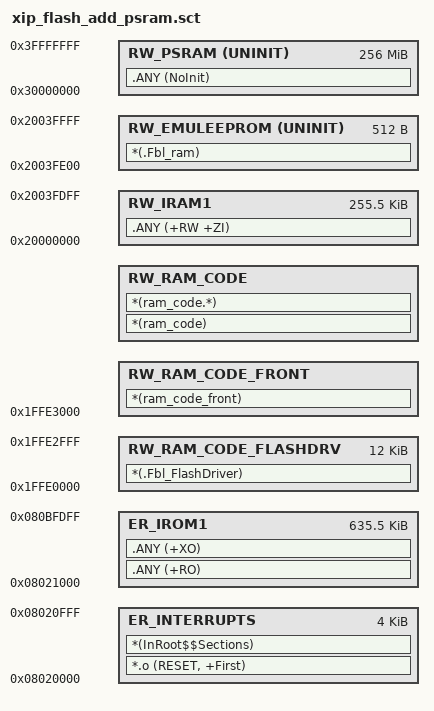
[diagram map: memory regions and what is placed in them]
; *************************************************************
; *** Scatter-Loading Description File generated by uVision ***
; *************************************************************
LR_INTERRUPTS 0x08020000 0x00001000  {    ; load region size_region
  ER_INTERRUPTS 0x08020000 0x00001000  {  ; load address = execution address
   *.o (RESET, +First)
   *(InRoot$$Sections)
  }
}

LR_IROM1 0x08021000 0x0009EE00  {    ; load region size_region
  ER_IROM1 0x08021000 0x0009EE00  {  ; load address = execution address
   .ANY (+RO)
   .ANY (+XO)
  }
  RW_RAM_CODE_FLASHDRV 0x1FFE0000 0x00003000 {
    *(.Fbl_FlashDriver)
  }
  RW_RAM_CODE_FRONT 0x1FFE3000  {
    *(ram_code_front)
  }
  RW_RAM_CODE +0 {
   *(ram_code)
   *(ram_code.*)
  }
  RW_IRAM1 0x20000000 0x0003FE00  {  ; RW data
   .ANY (+RW +ZI)
  }
  RW_EMULEEPROM 0x2003FE00 UNINIT 0x00000200{
    *(.Fbl_ram)
  }
  RW_PSRAM 0x30000000 UNINIT 0x10000000 {  ; RW data
   .ANY (NoInit)
  }
  
  ScatterAssert((ImageLength(RW_RAM_CODE_FRONT)+ImageLength(RW_RAM_CODE)) <= 0x1D000)
}

